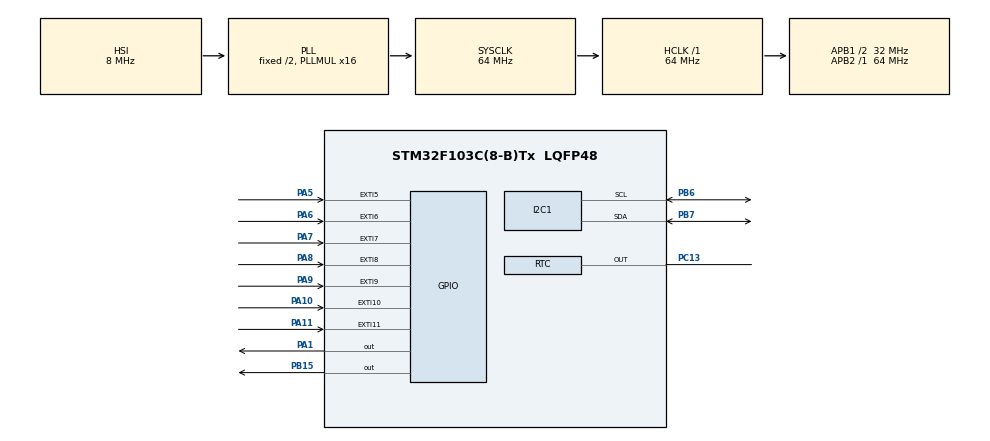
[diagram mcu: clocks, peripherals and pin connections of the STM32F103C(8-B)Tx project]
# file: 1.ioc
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Mcu.Family=STM32F1
Mcu.Name=STM32F103C(8-B)Tx
Mcu.Package=LQFP48
NVIC.EXTI15_10_IRQn=true\:0\:0\:false\:false\:true\:true\:true
NVIC.EXTI9_5_IRQn=true\:0\:0\:false\:false\:true\:true\:true
NVIC.I2C1_ER_IRQn=true\:0\:0\:false\:false\:true\:true\:true
NVIC.I2C1_EV_IRQn=true\:0\:0\:false\:false\:true\:true\:true
NVIC.PriorityGroup=NVIC_PRIORITYGROUP_4
NVIC.RTC_IRQn=true\:0\:0\:false\:false\:true\:true\:true
NVIC.TIM1_BRK_IRQn=true\:1\:0\:true\:false\:true\:true\:true
NVIC.TIM1_CC_IRQn=true\:1\:0\:true\:false\:true\:true\:true
NVIC.TIM1_TRG_COM_IRQn=true\:1\:0\:true\:false\:true\:true\:true
NVIC.TIM1_UP_IRQn=true\:1\:0\:true\:false\:true\:true\:true
PA1.GPIO_PuPd=GPIO_PULLUP
PA1.PinState=GPIO_PIN_SET
PA1.Signal=GPIO_Output
PA10.GPIO_ModeDefaultEXTI=GPIO_MODE_IT_FALLING
PA10.GPIO_PuPd=GPIO_PULLUP
PA10.Signal=GPXTI10
PA11.GPIO_ModeDefaultEXTI=GPIO_MODE_IT_FALLING
PA11.GPIO_PuPd=GPIO_PULLUP
PA11.Signal=GPXTI11
PA13.Mode=Serial_Wire
PA13.Signal=SYS_JTMS-SWDIO
PA14.Mode=Serial_Wire
PA14.Signal=SYS_JTCK-SWCLK
PA5.GPIO_ModeDefaultEXTI=GPIO_MODE_IT_FALLING
PA5.GPIO_PuPd=GPIO_PULLUP
PA5.Signal=GPXTI5
PA6.GPIO_ModeDefaultEXTI=GPIO_MODE_IT_FALLING
PA6.GPIO_PuPd=GPIO_PULLUP
PA6.Signal=GPXTI6
PA7.GPIO_ModeDefaultEXTI=GPIO_MODE_IT_FALLING
PA7.GPIO_PuPd=GPIO_PULLUP
PA7.Signal=GPXTI7
PA8.GPIO_ModeDefaultEXTI=GPIO_MODE_IT_FALLING
PA8.GPIO_PuPd=GPIO_PULLUP
PA8.Signal=GPXTI8
PA9.GPIO_ModeDefaultEXTI=GPIO_MODE_IT_FALLING
PA9.GPIO_PuPd=GPIO_PULLUP
PA9.Signal=GPXTI9
PB15.Signal=GPIO_Output
PB6.Mode=I2C
PB6.Signal=I2C1_SCL
PB7.Mode=I2C
PB7.Signal=I2C1_SDA
PC13-TAMPER-RTC.Mode=RTC OUT
PC13-TAMPER-RTC.Signal=RTC_OUT
ProjectManager.HeapSize=0x200
ProjectManager.StackSize=0x400
ProjectManager.TargetToolchain=MDK-ARM V5.27
RCC.AHBFreq_Value=64000000
RCC.APB1CLKDivider=RCC_HCLK_DIV2
RCC.APB1Freq_Value=32000000
RCC.APB1TimFreq_Value=64000000
RCC.APB2Freq_Value=64000000
RCC.APB2TimFreq_Value=64000000
RCC.HCLKFreq_Value=64000000
RCC.PLLMUL=RCC_PLL_MUL16
RCC.SYSCLKFreq_VALUE=64000000
RCC.SYSCLKSource=RCC_SYSCLKSOURCE_PLLCLK
RCC.USBFreq_Value=64000000
RTC.Format=RTC_FORMAT_BIN
RTC.OutPut=RTC_OUTPUTSOURCE_ALARM
RTC.Seconds_A-RTC\ OUT=2
TIM1.Period=999
TIM1.Prescaler=63
VP_CRC_VS_CRC.Mode=CRC_Activate
VP_RTC_VS_RTC_Activate.Mode=RTC_Enabled
VP_RTC_VS_RTC_Calendar.Mode=RTC_Calendar
VP_TIM1_VS_ClockSourceINT.Mode=Internal
board=custom

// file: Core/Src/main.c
/* USER CODE BEGIN Header */
/**
  ******************************************************************************
  * @file           : main.c
  * @brief          : Main program body
  ******************************************************************************
  * @attention
  *
  * <h2><center>&copy; Copyright (c) 2022 STMicroelectronics.
  * All rights reserved.</center></h2>
  *
  * This software component is licensed by ST under BSD 3-Clause license,
  * the "License"; You may not use this file except in compliance with the
  * License. You may obtain a copy of the License at:
  *                        opensource.org/licenses/BSD-3-Clause
  *
  ******************************************************************************
  */
/* USER CODE END Header */
#include "main.h"
#include "crc.h"
#include "i2c.h"
#include "rtc.h"
#include "tim.h"
#include "gpio.h"

/* USER CODE BEGIN Includes */
#include "main_task.h"
/* USER CODE END Includes */

void SystemClock_Config(void);

int main(void)
{

  /* MCU Configuration--------------------------------------------------------*/

  /* Reset of all peripherals, Initializes the Flash interface and the Systick. */
  HAL_Init();

  /* Configure the system clock */
  SystemClock_Config();

  /* Initialize all configured peripherals */
  MX_GPIO_Init();
  MX_CRC_Init();
  MX_I2C1_Init();
  MX_RTC_Init();
  MX_TIM1_Init();
  /* USER CODE BEGIN 2 */
		main_init();
  /* USER CODE END 2 */

  /* Infinite loop */
  while (1)
  {

    /* USER CODE BEGIN 3 */
			main_task();
  }
  /* USER CODE END 3 */
}

void SystemClock_Config(void)
{
  RCC_OscInitTypeDef RCC_OscInitStruct = {0};
  RCC_ClkInitTypeDef RCC_ClkInitStruct = {0};
  RCC_PeriphCLKInitTypeDef PeriphClkInit = {0};

  /** Initializes the RCC Oscillators according to the specified parameters
  * in the RCC_OscInitTypeDef structure.
  */
  RCC_OscInitStruct.OscillatorType = RCC_OSCILLATORTYPE_HSI|RCC_OSCILLATORTYPE_LSI;
  RCC_OscInitStruct.HSIState = RCC_HSI_ON;
  RCC_OscInitStruct.HSICalibrationValue = RCC_HSICALIBRATION_DEFAULT;
  RCC_OscInitStruct.LSIState = RCC_LSI_ON;
  RCC_OscInitStruct.PLL.PLLState = RCC_PLL_ON;
  RCC_OscInitStruct.PLL.PLLSource = RCC_PLLSOURCE_HSI_DIV2;
  RCC_OscInitStruct.PLL.PLLMUL = RCC_PLL_MUL16;
  if (HAL_RCC_OscConfig(&RCC_OscInitStruct) != HAL_OK)
  {
    Error_Handler();
  }
  /** Initializes the CPU, AHB and APB buses clocks
  */
  RCC_ClkInitStruct.ClockType = RCC_CLOCKTYPE_HCLK|RCC_CLOCKTYPE_SYSCLK
                              |RCC_CLOCKTYPE_PCLK1|RCC_CLOCKTYPE_PCLK2;
  RCC_ClkInitStruct.SYSCLKSource = RCC_SYSCLKSOURCE_PLLCLK;
  RCC_ClkInitStruct.AHBCLKDivider = RCC_SYSCLK_DIV1;
  RCC_ClkInitStruct.APB1CLKDivider = RCC_HCLK_DIV2;
  RCC_ClkInitStruct.APB2CLKDivider = RCC_HCLK_DIV1;

  if (HAL_RCC_ClockConfig(&RCC_ClkInitStruct, FLASH_LATENCY_2) != HAL_OK)
  {
    Error_Handler();
  }
  PeriphClkInit.PeriphClockSelection = RCC_PERIPHCLK_RTC;
  PeriphClkInit.RTCClockSelection = RCC_RTCCLKSOURCE_LSI;
  if (HAL_RCCEx_PeriphCLKConfig(&PeriphClkInit) != HAL_OK)
  {
    Error_Handler();
  }
}

void Error_Handler(void)
{
  __disable_irq();
  while (1)
  {
  }
}

/************************ (C) COPYRIGHT STMicroelectronics *****END OF FILE****/
